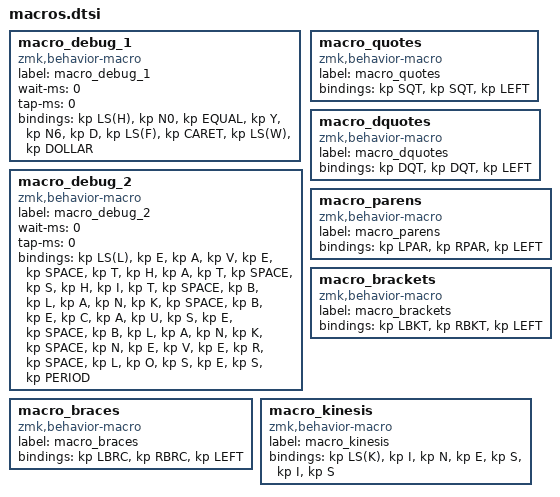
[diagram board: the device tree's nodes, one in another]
  macro_debug_1: macro_debug_1{
    compatible = "zmk,behavior-macro";
    label = "macro_debug_1";
    wait-ms = <0>;
    tap-ms = <0>;
    #binding-cells = <0>;
    bindings = <&kp LS(H) &kp N0 &kp EQUAL &kp Y &kp N6 &kp D &kp LS(F) &kp CARET &kp LS(W) &kp DOLLAR>;
  };
  macro_debug_2: macro_debug_2{
    compatible = "zmk,behavior-macro";
    label = "macro_debug_2";
    wait-ms = <0>;
    tap-ms = <0>;
    #binding-cells = <0>;
    bindings = <&kp LS(L) &kp E &kp A &kp V &kp E &kp SPACE &kp T &kp H &kp A &kp T &kp SPACE &kp S &kp H &kp I &kp T &kp SPACE &kp B &kp L &kp A &kp N &kp K &kp SPACE &kp B &kp E &kp C &kp A &kp U &kp S &kp E &kp SPACE &kp B &kp L &kp A &kp N &kp K &kp SPACE &kp N &kp E &kp V &kp E &kp R &kp SPACE &kp L &kp O &kp S &kp E &kp S &kp PERIOD>;
  };

  macro_quotes: macro_quotes {
    compatible = "zmk,behavior-macro";
    label = "macro_quotes";
    #binding-cells = <0>;
    bindings = <&kp SQT>, <&kp SQT>, <&kp LEFT>;
  };
  macro_dquotes: macro_dquotes {
    compatible = "zmk,behavior-macro";
    label = "macro_dquotes";
    #binding-cells = <0>;
    bindings = <&kp DQT>, <&kp DQT>, <&kp LEFT>;
  };
  macro_braces: macro_braces {
    compatible = "zmk,behavior-macro";
    label = "macro_braces";
    #binding-cells = <0>;
    bindings = <&kp LBRC>, <&kp RBRC>, <&kp LEFT>;
  };
  macro_parens: macro_parens {
    compatible = "zmk,behavior-macro";
    label = "macro_parens";
    #binding-cells = <0>;
    bindings = <&kp LPAR>, <&kp RPAR>, <&kp LEFT>;
  };
  macro_brackets: macro_brackets {
    compatible = "zmk,behavior-macro";
    label = "macro_brackets";
    #binding-cells = <0>;
    bindings = <&kp LBKT>, <&kp RBKT>, <&kp LEFT>;
  };
  macro_kinesis: macro_kinesis {
    compatible = "zmk,behavior-macro";
    label = "macro_kinesis";
    #binding-cells = <0>;
    bindings = <&kp LS(K)>, <&kp I>, <&kp N>, <&kp E>, <&kp S>, <&kp I>, <&kp S>;
  };
